# SIM3L168_A register map
File version: 1
CPU: 
Registers are 32-bit, read-write, reset 0x0 unless marked. A register's access mark holds for its fields unless they carry their own. Offsets are from the block's base; [hi:lo] are bit positions; {n}, {i} and the like mark numbered series.

## PMU_0
Base 0x40048000
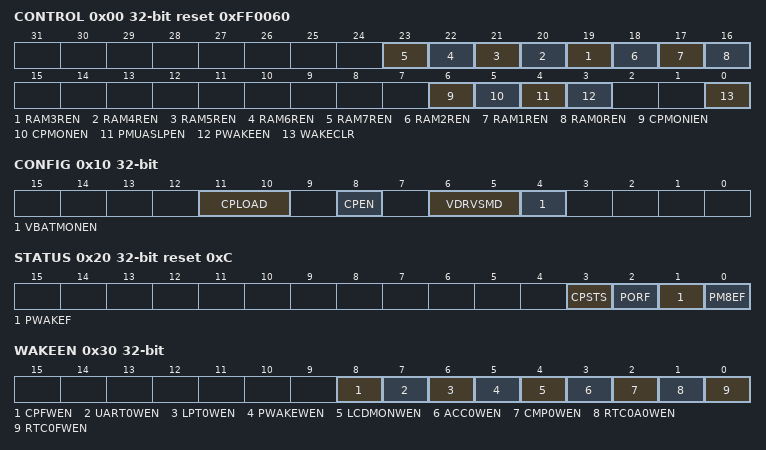
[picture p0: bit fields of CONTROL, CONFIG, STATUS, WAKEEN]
0x00 CONTROL reset 0xFF0060 — Module Control
  [n+16] RAM{n}REN (n=3..7) — RAM {n} Retention Enable.
    0=DISABLED (Disable power to RAM {n} (4 kB addresses from {0x20000000+0x1000*n} to {0x20000FFF+0x1000*n}).); 1=ENABLED (Disable power to RAM {n} (4 kB addresses from {0x20000000+0x1000*n} to {0x20000FFF+0x1000*n}).)
  [18] RAM2REN — RAM 2 Retention Enable.
    0=DISABLED (Disable power to RAM 0 (4 kB addresses from 0x20002000 to 0x20002FFF).); 1=ENABLED (Disable power to RAM 0 (4 kB addresses from 0x20002000 to 0x20002FFF).)
  [17] RAM1REN — RAM 1 Retention Enable.
    0=DISABLED (Disable power to RAM 1 (4 kB addresses from 0x20001000 to 0x20001FFF).); 1=ENABLED (Disable power to RAM 1 (4 kB addresses from 0x20001000 to 0x20001FFF).)
  [16] RAM0REN — RAM 0 Retention Enable.
    0=DISABLED (Disable power to RAM 0 (4 kB addresses from 0x20000000 to 0x20000FFF).); 1=ENABLED (Disable power to RAM 0 (4 kB addresses from 0x20000000 to 0x20000FFF).)
  [6] CPMONIEN — Low Power Charge Pump Voltage Monitor Interrupt Enable.
    0=DISABLED (Disable the low power charge pump voltage monitor interrupt.); 1=ENABLED (Enable the low power charge pump voltage monitor interrupt.)
  [5] CPMONEN — Low Power Charge Pump Voltage Monitor Enable.
    0=DISABLED (Disable the low power charge pump voltage monitor.); 1=ENABLED (Enable the low power charge pump voltage monitor.)
  [4] PMUASLPEN — PMU Asleep Pin Enable.
    0=DISABLED (Disable the PMU Asleep pin.); 1=ENABLED (Enable the PMU Asleep pin.)
  [3] PWAKEEN — Pin Wake Match Enable.
    0=DISABLED (Disable Pin Wake.); 1=ENABLED (Enable Pin Wake.)
  [0] WAKECLR wo — Wakeup Source Clear.
    0=CLEAR (Clear all wakeup sources.)
0x10 CONFIG — Module Configuration
  [11:10] CPLOAD — Charge Pump Load Setting.
  [8] CPEN — Low Power Charge Pump Enable.
    0=DISABLED; 1=ENABLED
  [6:5] VDRVSMD — VDRV Switch Mode.
    0=HIGHZ; 2=VBAT (VBAT connected to VDRV.); 3=VDC (DC-DC output connected to VDRV.)
  [4] VBATMONEN — VBAT Monitor Disable.
    0=ENABLED (Enable the 0.8 V VBAT monitor.); 1=DISABLED (Disable the 0.8V VBAT monitor.)
0x20 STATUS reset 0xC — Module Status
  [3] CPSTS ro — Low Power Charge Pump Voltage Monitor Status.
    0=NOT_SET (The low power charge pump supply voltage is below the threshold.); 1=SET (The low power charge pump supply voltage is greater than the threshold.)
  [2] PORF — Power-On Reset Flag.
    0=NOT_SET (A power-on reset did not occur since the last time PORF was cleared.); 1=SET (A power-on reset occurred.)
  [1] PWAKEF ro — Pin Wake Status Flag.
    0=NOT_SET (A Pin Wake event has not occurred.); 1=SET (A Pin Wake event has occurred.)
  [0] PM8EF — Power Mode 8 Exited Flag.
    0=NOT_SET (The device has not exited Power Mode 8.); 1=SET (The device has exited Power Mode 8. This bit must be cleared by firmware.)
0x30 WAKEEN — Wakeup Enable
  [8] CPFWEN — Low Power Charge Pump Supply Fail Wake Enable.
    0=DISABLED (A low power charge pump supply fail event does not wake the device.); 1=ENABLED (A low power charge pump supply fail event awakens the device.)
  [7] UART0WEN — UART0 Wake Enable.
    0=DISABLED (A UART0 event does not wake the device.); 1=ENABLED (A UART0 event awakens the device.)
  [6] LPT0WEN — Low Power Timer Wake Enable.
    0=DISABLED (An LPTIMER0 event does not wake the device.); 1=ENABLED (An LPTIMER0 event awakens the device.)
  [5] PWAKEWEN — Pin Wake Wake Enable.
    0=DISABLED (A Pin Wake event does not wake the device.); 1=ENABLED (A Pin Wake event awakens the device.)
  [4] LCDMONWEN — LCD VBAT Voltage Monitor Wake Enable.
    0=DISABLED (An LCD VBAT voltage monitor event does not wake the device.); 1=ENABLED (An LCD VBAT voltage monitor event awakens the device.)
  [3] ACC0WEN — Advanced Capture Counter 0 Wake Enable.
    0=DISABLED (An Advanced Capture Counter (ACCTR0) event does not wake the device.); 1=ENABLED (An Advanced Capture Counter (ACCTR0) event awakens the device.)
  [2] CMP0WEN — Comparator 0 Wake Enable.
    0=DISABLED (A Comparator 0 event does not wake the device.); 1=ENABLED (A Comparator 0 event awakens the device.)
  [1] RTC0A0WEN — RTC0 Alarm 0 Wake Enable.
    0=DISABLED (An RTC0 Alarm 0 event does not wake the device.); 1=ENABLED (An RTC0 Alarm 0 event awakens the device.)
  [0] RTC0FWEN — RTC0 Fail Wake Enable.
    0=DISABLED (An RTC0 Fail event does not wake the device.); 1=ENABLED (An RTC0 Fail event awakens the device.)
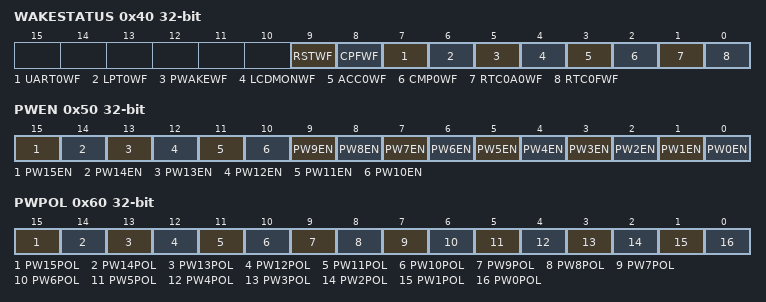
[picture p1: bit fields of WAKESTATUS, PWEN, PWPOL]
0x40 WAKESTATUS — Wakeup Status
  [9] RSTWF ro — Reset Pin Wake Flag.
    0=NOT_SET (A /RESET Pin event did not wake the device.); 1=SET (A /RESET Pin event woke the device.)
  [8] CPFWF ro — Low Power Charge Pump Supply Fail Wake Flag.
    0=NOT_SET (A low power charge pump supply fail event did not wake the device.); 1=SET (A low power charge pump supply fail event woke the device.)
  [7] UART0WF ro — UART0 Wake Flag.
    0=NOT_SET (A UART0 event did not wake the device.); 1=SET (A UART0 event woke the device.)
  [6] LPT0WF ro — Low Power Timer Wake Flag.
    0=NOT_SET (An LPTIMER0 event did not wake the device.); 1=SET (An LPTIMER0 event woke the device.)
  [5] PWAKEWF ro — Pin Wake Wake Flag.
    0=NOT_SET (A Pin Wake event did not wake the device.); 1=SET (A Pin Wake event woke the device.)
  [4] LCDMONWF ro — LCD VBAT Voltage Monitor Wake Flag.
    0=NOT_SET (A LCD VBAT voltage monitor event did not wake the device.); 1=SET (A LCD VBAT voltage monitor event woke the device.)
  [3] ACC0WF ro — Advanced Capture Counter 0 Wake Flag.
    0=NOT_SET (An Advanced Capture Counter (ACCTR0) event did not wake the device.); 1=SET (An Advanced Capture Counter (ACCTR0) event woke the device.)
  [2] CMP0WF ro — Comparator 0 Wake Flag.
    0=NOT_SET (A Comparator 0 event did not wake the device.); 1=SET (A Comparator 0 event woke the device.)
  [1] RTC0A0WF ro — RTC0 Alarm 0 Wake Flag.
    0=NOT_SET (An RTC0 Alarm 0 event did not wake the device.); 1=SET (An RTC0 0 Alarm event woke the device.)
  [0] RTC0FWF ro — RTC0 Fail Wake Flag.
    0=NOT_SET (An RTC0 Fail event did not wake the device.); 1=SET (An RTC0 Fail event woke the device.)
0x50 PWEN — Pin Wake Pin Enable
  [15] PW15EN — WAKE.15 Enable.
    0=DISABLED (WAKE.15 does not cause a Pin Wake event.); 1=ENABLED (Enable WAKE.15 as a Pin Wake source.)
  [14] PW14EN — WAKE.14 Enable.
    0=DISABLED (WAKE.14 does not cause a Pin Wake event.); 1=ENABLED (Enable WAKE.14 as a Pin Wake source.)
  [13] PW13EN — WAKE.13 Enable.
    0=DISABLED (WAKE.13 does not cause a Pin Wake event.); 1=ENABLED (Enable WAKE.13 as a Pin Wake source.)
  [12] PW12EN — WAKE.12 Enable.
    0=DISABLED (WAKE.12 does not cause a Pin Wake event.); 1=ENABLED (Enable WAKE.12 as a Pin Wake source.)
  [11] PW11EN — WAKE.11 Enable.
    0=DISABLED (WAKE.11 does not cause a Pin Wake event.); 1=ENABLED (Enable WAKE.11 as a Pin Wake source.)
  [10] PW10EN — WAKE.10 Enable.
    0=DISABLED (WAKE.10 does not cause a Pin Wake event.); 1=ENABLED (Enable WAKE.10 as a Pin Wake source.)
  [9] PW9EN — WAKE.9 Enable.
    0=DISABLED (WAKE.9 does not cause a Pin Wake event.); 1=ENABLED (Enable WAKE.9 as a Pin Wake source.)
  [8] PW8EN — WAKE.8 Enable.
    0=DISABLED (WAKE.8 does not cause a Pin Wake event.); 1=ENABLED (Enable WAKE.8 as a Pin Wake source.)
  [7] PW7EN — WAKE.7 Enable.
    0=DISABLED (WAKE.7 does not cause a Pin Wake event.); 1=ENABLED (Enable WAKE.7 as a Pin Wake source.)
  [6] PW6EN — WAKE.6 Enable.
    0=DISABLED (WAKE.6 does not cause a Pin Wake event.); 1=ENABLED (Enable WAKE.6 as a Pin Wake source.)
  [5] PW5EN — WAKE.5 Enable.
    0=DISABLED (WAKE.5 does not cause a Pin Wake event.); 1=ENABLED (Enable WAKE.5 as a Pin Wake source.)
  [4] PW4EN — WAKE.4 Enable.
    0=DISABLED (WAKE.4 does not cause a Pin Wake event.); 1=ENABLED (Enable WAKE.4 as a Pin Wake source.)
  [3] PW3EN — WAKE.3 Enable.
    0=DISABLED (WAKE.3 does not cause a Pin Wake event.); 1=ENABLED (Enable WAKE.3 as a Pin Wake source.)
  [2] PW2EN — WAKE.2 Enable.
    0=DISABLED (WAKE.2 does not cause a Pin Wake event.); 1=ENABLED (Enable WAKE.2 as a Pin Wake source.)
  [1] PW1EN — WAKE.1 Enable.
    0=DISABLED (WAKE.1 does not cause a Pin Wake event.); 1=ENABLED (Enable WAKE.1 as a Pin Wake source.)
  [0] PW0EN — WAKE.0 Enable.
    0=DISABLED (WAKE.0 does not cause a Pin Wake event.); 1=ENABLED (Enable WAKE.0 as a Pin Wake source.)
0x60 PWPOL — Pin Wake Pin Polarity Select
  [15] PW15POL — WAKE.15 Polarity Select.
    0=LOW (A logic low on WAKE.15 causes a Pin Wake event if PW15EN is set to 1.); 1=HIGH (A logic high on WAKE.15 causes a Pin Wake event if PW15EN is set to 1.)
  [14] PW14POL — WAKE.14 Polarity Select.
    0=LOW (A logic low on WAKE.14 causes a Pin Wake event if PW14EN is set to 1.); 1=HIGH (A logic high on WAKE.14 causes a Pin Wake event if PW14EN is set to 1.)
  [13] PW13POL — WAKE.13 Polarity Select.
    0=LOW (A logic low on WAKE.13 causes a Pin Wake event if PW13EN is set to 1.); 1=HIGH (A logic high on WAKE.13 causes a Pin Wake event if PW13EN is set to 1.)
  [12] PW12POL — WAKE.12 Polarity Select.
    0=LOW (A logic low on WAKE.12 causes a Pin Wake event if PW12EN is set to 1.); 1=HIGH (A logic high on WAKE.12 causes a Pin Wake event if PW12EN is set to 1.)
  [11] PW11POL — WAKE.11 Polarity Select.
    0=LOW (A logic low on WAKE.11 causes a Pin Wake event if PW11EN is set to 1.); 1=HIGH (A logic high on WAKE.11 causes a Pin Wake event if PW11EN is set to 1.)
  [10] PW10POL — WAKE.10 Polarity Select.
    0=LOW (A logic low on WAKE.10 causes a Pin Wake event if PW10EN is set to 1.); 1=HIGH (A logic high on WAKE.10 causes a Pin Wake event if PW10EN is set to 1.)
  [9] PW9POL — WAKE.9 Polarity Select.
    0=LOW (A logic low on WAKE.9 causes a Pin Wake event if PW9EN is set to 1.); 1=HIGH (A logic high on WAKE.9 causes a Pin Wake event if PW9EN is set to 1.)
  [8] PW8POL — WAKE.8 Polarity Select.
    0=LOW (A logic low on WAKE.8 causes a Pin Wake event if PW8EN is set to 1.); 1=HIGH (A logic high on WAKE.8 causes a Pin Wake event if PW8EN is set to 1.)
  [7] PW7POL — WAKE.7 Polarity Select.
    0=LOW (A logic low on WAKE.7 causes a Pin Wake event if PW7EN is set to 1.); 1=HIGH (A logic high on WAKE.7 causes a Pin Wake event if PW7EN is set to 1.)
  [6] PW6POL — WAKE.6 Polarity Select.
    0=LOW (A logic low on WAKE.6 causes a Pin Wake event if PW6EN is set to 1.); 1=HIGH (A logic high on WAKE.6 causes a Pin Wake event if PW6EN is set to 1.)
  [5] PW5POL — WAKE.5 Polarity Select.
    0=LOW (A logic low on WAKE.5 causes a Pin Wake event if PW5EN is set to 1.); 1=HIGH (A logic high on WAKE.5 causes a Pin Wake event if PW5EN is set to 1.)
  [4] PW4POL — WAKE.4 Polarity Select.
    0=LOW (A logic low on WAKE.4 causes a Pin Wake event if PW4EN is set to 1.); 1=HIGH (A logic high on WAKE.4 causes a Pin Wake event if PW4EN is set to 1.)
  [3] PW3POL — WAKE.3 Polarity Select.
    0=LOW (A logic low on WAKE.3 causes a Pin Wake event if PW3EN is set to 1.); 1=HIGH (A logic high on WAKE.3 causes a Pin Wake event if PW3EN is set to 1.)
  [2] PW2POL — WAKE.2 Polarity Select.
    0=LOW (A logic low on WAKE.2 causes a Pin Wake event if PW2EN is set to 1.); 1=HIGH (A logic high on WAKE.2 causes a Pin Wake event if PW2EN is set to 1.)
  [1] PW1POL — WAKE.1 Polarity Select.
    0=LOW (A logic low on WAKE.1 causes a Pin Wake event if PW1EN is set to 1.); 1=HIGH (A logic high on WAKE.1 causes a Pin Wake event if PW1EN is set to 1.)
  [0] PW0POL — WAKE.0 Polarity Select.
    0=LOW (A logic low on WAKE.0 causes a Pin Wake event if PW0EN is set to 1.); 1=HIGH (A logic high on WAKE.0 causes a Pin Wake event if PW0EN is set to 1.)
